# NV32F100 register map
File version: 1.6
Registers are 32-bit, read-write, reset 0x0 unless marked. A register's access mark holds for its fields unless they carry their own. Offsets are from the block's base; [hi:lo] are bit positions; {n}, {i} and the like mark numbered series; 'fields as' and 'values as' point back to an identical list.

## FTFA — Flash Memory Interface
Base 0x40020000; register names take the prefix FTFA_
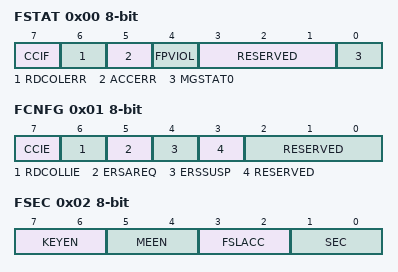
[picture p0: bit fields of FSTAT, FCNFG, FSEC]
0x00 FSTAT 8-bit — Flash Status Register
  [7] CCIF — Command Complete Interrupt Flag
    0=Flash command in progress; 1=Flash command has completed
  [6] RDCOLERR — Flash Read Collision Error Flag
    0=No collision error detected; 1=Collision error detected
  [5] ACCERR — Flash Access Error Flag
    0=No access error detected; 1=Access error detected
  [4] FPVIOL — Flash Protection Violation Flag
    0=No protection violation detected; 1=Protection violation detected
  [3:1] RESERVED ro
  [0] MGSTAT0 ro — Memory Controller Command Completion Status Flag
0x01 FCNFG 8-bit — Flash Configuration Register
  [7] CCIE — Command Complete Interrupt Enable
    0=Command complete interrupt disabled; 1=Command complete interrupt enabled. An interrupt request is generated whenever the FSTAT[CCIF] flag is set.
  [6] RDCOLLIE — Read Collision Error Interrupt Enable
    0=Read collision error interrupt disabled; 1=Read collision error interrupt enabled. An interrupt request is generated whenever a flash memory read collision error is detected (see the description of FSTAT[RDCOLERR]).
  [5] ERSAREQ ro — Erase All Request
    0=No request or request complete; 1=Request to: run the Erase All Blocks command, verify the erased state, program the security byte in the Flash Configuration Field to the unsecure state, and release MCU security by setting the FSEC[SEC] field to the unsecure state
  [4] ERSSUSP — Erase Suspend
    0=No suspend requested; 1=Suspend the current Erase Flash Sector command execution
  [3] RESERVED ro
  [2:0] RESERVED ro
0x02 FSEC 8-bit ro reset not defined — Flash Security Register
  [7:6] KEYEN — Backdoor Key Security Enable
    0=Backdoor key access disabled; 1=Backdoor key access disabled (preferred KEYEN state to disable backdoor key access); 2=Backdoor key access enabled; 3=Backdoor key access disabled
  [5:4] MEEN — Mass Erase Enable Bits
    0=Mass erase is enabled; 1=Mass erase is enabled; 2=Mass erase is disabled; 3=Mass erase is enabled
  [3:2] FSLACC — Freescale Failure Analysis Access Code
    0=Freescale factory access granted; 1=Freescale factory access denied; 2=Freescale factory access denied; 3=Freescale factory access granted
  [1:0] SEC — Flash Security
    0=MCU security status is secure; 1=MCU security status is secure; 2=MCU security status is unsecure (The standard shipping condition of the flash memory module is unsecure.); 3=MCU security status is secure
0x03 FOPT 8-bit ro reset not defined — Flash Option Register
  [7:0] OPT — Nonvolatile Option
0x04 FCCOB{x} (x=3,2,1,0,7,6,5,4,B,A,9,8; step 0x1) 8-bit — Flash Common Command Object Registers
  [7:0] CCOBn
0x10 FPROT{x} (x=3,2,1,0; step 0x1) 8-bit reset not defined — Program Flash Protection Registers
  [7:0] PROT — Program Flash Region Protect
    0=Program flash region is protected; 1=Program flash region is not protected

## TPM0 — Timer/PWM Module
Base 0x40038000; register names take the prefix TPM0_
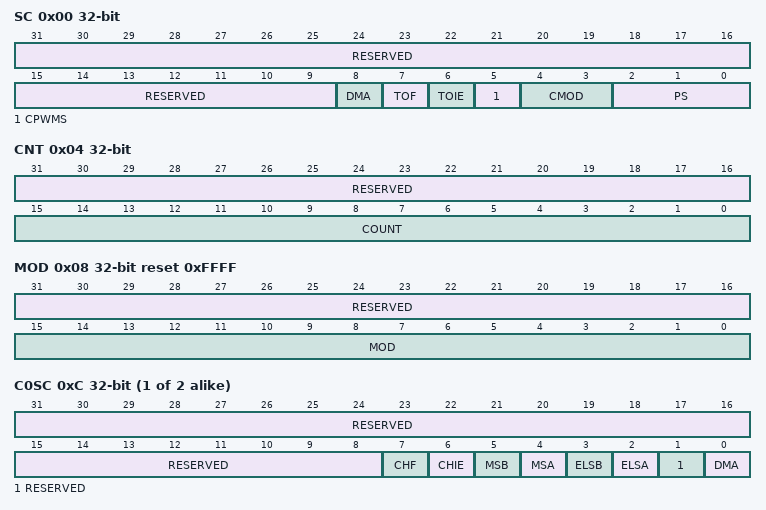
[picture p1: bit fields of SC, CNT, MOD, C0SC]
0x00 SC — Status and Control
  [31:9] RESERVED ro
  [8] DMA — DMA Enable
    0=Disables DMA transfers; 1=Enables DMA transfers
  [7] TOF — Timer Overflow Flag
    0=LPTPM counter has not overflowed; 1=LPTPM counter has overflowed
  [6] TOIE — Timer Overflow Interrupt Enable
    0=Disable TOF interrupts. Use software polling or DMA request.; 1=Enable TOF interrupts. An interrupt is generated when TOF equals one.
  [5] CPWMS — Center-aligned PWM Select
    0=LPTPM counter operates in up counting mode; 1=LPTPM counter operates in up-down counting mode
  [4:3] CMOD — Clock Mode Selection
    0=LPTPM counter is disabled; 1=LPTPM counter increments on every LPTPM counter clock; 2=LPTPM counter increments on rising edge of LPTPM_EXTCLK synchronized to the LPTPM counter clock
  [2:0] PS — Prescale Factor Selection
    0=Divide by 1; 1=Divide by 2; 2=Divide by 4; 3=Divide by 8; 4=Divide by 16; 5=Divide by 32; 6=Divide by 64; 7=Divide by 128
0x04 CNT — Counter
  [31:16] RESERVED ro
  [15:0] COUNT — Counter value
0x08 MOD reset 0xFFFF — Modulo
  [31:16] RESERVED ro
  [15:0] MOD — Modulo value
{0xC+8i} C{i}SC (i=0..1) — Channel (n) Status and Control
  [31:8] RESERVED ro
  [7] CHF — Channel Flag
    0=No channel event has occurred; 1=A channel event has occurred
  [6] CHIE — Channel Interrupt Enable
    0=Disable channel interrupts; 1=Enable channel interrupts
  [5] MSB — Channel Mode Select
  [4] MSA — Channel Mode Select
  [3] ELSB — Edge or Level Select
  [2] ELSA — Edge or Level Select
  [1] RESERVED ro
  [0] DMA — DMA Enable
    0=Disable DMA transfers; 1=Enable DMA transfers
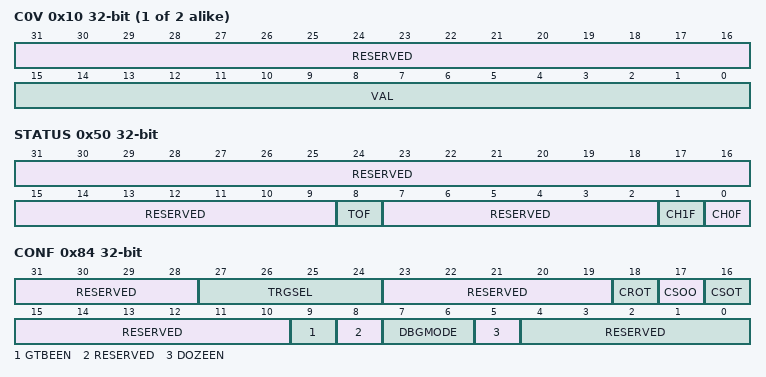
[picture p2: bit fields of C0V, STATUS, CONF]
{0x10+8i} C{i}V (i=0..1) — Channel (n) Value
  [31:16] RESERVED ro
  [15:0] VAL — Channel Value
0x50 STATUS — Capture and Compare Status
  [31:9] RESERVED ro
  [8] TOF — Timer Overflow Flag
    values as SC.TOF
  [7:2] RESERVED ro
  [1] CH1F — Channel 1 Flag
    values as C0SC.CHF
  [0] CH0F — Channel 0 Flag
    values as C0SC.CHF
0x84 CONF — Configuration
  [31:28] RESERVED ro
  [27:24] TRGSEL — Trigger Select
  [23:19] RESERVED ro
  [18] CROT — Counter Reload On Trigger
    0=Counter is not reloaded due to a rising edge on the selected input trigger; 1=Counter is reloaded when a rising edge is detected on the selected input trigger
  [17] CSOO — Counter Stop On Overflow
    0=LPTPM counter continues incrementing or decrementing after overflow; 1=LPTPM counter stops incrementing or decrementing after overflow
  [16] CSOT — Counter Start on Trigger
    0=LPTPM counter starts to increment immediately, once it is enabled; 1=LPTPM counter only starts to increment when it a rising edge on the selected input trigger is detected, after it has been enabled or after it has stopped due to overflow
  [15:10] RESERVED ro
  [9] GTBEEN — Global time base enable
    0=All channels use the internally generated LPTPM counter as their timebase; 1=All channels use an externally generated global timebase as their timebase
  [8] RESERVED ro
  [7:6] DBGMODE — Debug Mode
    0=LPTPM counter is paused and does not increment during debug mode. Trigger inputs and input capture events are also ignored.; 3=LPTPM counter continues in debug mode
  [5] DOZEEN — Doze Enable
    0=Internal LPTPM counter continues in Doze mode; 1=Internal LPTPM counter is paused and does not increment during Doze mode. Trigger inputs and input capture events are also ignored.
  [4:0] RESERVED ro

## TPM1 — Timer/PWM Module
Base 0x40039000; register names take the prefix TPM1_
Registers as TPM0.
